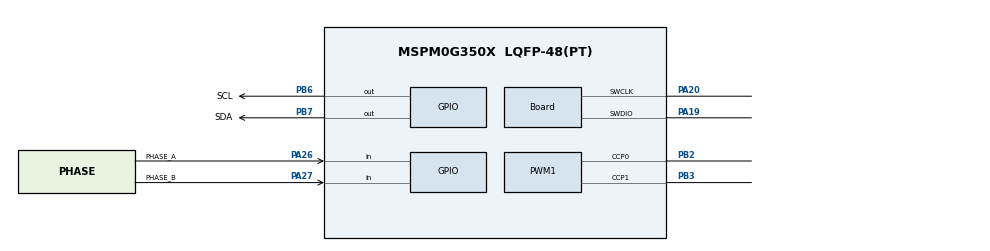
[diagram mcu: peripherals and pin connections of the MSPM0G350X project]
/**
 * @cliArgs --device "MSPM0G350X" --package "LQFP-48(PT)" --part "Default" --product "mspm0_sdk@2.01.00.03"
 * @versions {"tool":"1.20.0+3587"}
 */

/**
 * Import the modules used in this configuration.
 */
const GPIO          = scripting.addModule("/ti/driverlib/GPIO", {}, false);
const GPIO1         = GPIO.addInstance();
const GPIO2         = GPIO.addInstance();
const GPIO3         = GPIO.addInstance();
const PWM           = scripting.addModule("/ti/driverlib/PWM", {}, false);
const PWM1          = PWM.addInstance();
const SYSCTL        = scripting.addModule("/ti/driverlib/SYSCTL");
const ProjectConfig = scripting.addModule("/ti/project_config/ProjectConfig");

/**
 * Write custom configuration values to the imported modules.
 */
GPIO1.$name                              = "GPIO_OLED";
GPIO1.associatedPins.create(2);
GPIO1.associatedPins[0].$name            = "SCL";
GPIO1.associatedPins[0].initialValue     = "SET";
GPIO1.associatedPins[0].internalResistor = "PULL_UP";
GPIO1.associatedPins[0].assignedPort     = "PORTB";
GPIO1.associatedPins[0].assignedPin      = "6";
GPIO1.associatedPins[0].pin.$assign      = "PB6";
GPIO1.associatedPins[1].$name            = "SDA";
GPIO1.associatedPins[1].initialValue     = "SET";
GPIO1.associatedPins[1].internalResistor = "PULL_UP";
GPIO1.associatedPins[1].assignedPort     = "PORTB";
GPIO1.associatedPins[1].assignedPin      = "7";
GPIO1.associatedPins[1].pin.$assign      = "PB7";

const Board                       = scripting.addModule("/ti/driverlib/Board", {}, false);
Board.peripheral.$assign          = "DEBUGSS";
Board.peripheral.swclkPin.$assign = "PA20";
Board.peripheral.swdioPin.$assign = "PA19";

GPIO2.$name                              = "GPIO_ENCODER";
GPIO2.associatedPins.create(2);
GPIO2.associatedPins[0].$name            = "PHASE_A";
GPIO2.associatedPins[0].direction        = "INPUT";
GPIO2.associatedPins[0].internalResistor = "PULL_UP";
GPIO2.associatedPins[0].assignedPort     = "PORTA";
GPIO2.associatedPins[0].assignedPin      = "26";
GPIO2.associatedPins[0].interruptEn      = true;
GPIO2.associatedPins[0].polarity         = "RISE_FALL";
GPIO2.associatedPins[0].pin.$assign      = "PA26";
GPIO2.associatedPins[1].$name            = "PHASE_B";
GPIO2.associatedPins[1].direction        = "INPUT";
GPIO2.associatedPins[1].internalResistor = "PULL_UP";
GPIO2.associatedPins[1].assignedPort     = "PORTA";
GPIO2.associatedPins[1].assignedPin      = "27";
GPIO2.associatedPins[1].interruptEn      = true;
GPIO2.associatedPins[1].polarity         = "RISE_FALL";
GPIO2.associatedPins[1].pin.$assign      = "PA27";

GPIO3.$name                          = "GPIO_MOTOR";
GPIO3.associatedPins.create(4);
GPIO3.associatedPins[0].$name        = "LIN1";
GPIO3.associatedPins[0].assignedPort = "PORTB";
GPIO3.associatedPins[0].assignedPin  = "18";
GPIO3.associatedPins[1].$name        = "LIN2";
GPIO3.associatedPins[1].assignedPort = "PORTB";
GPIO3.associatedPins[1].assignedPin  = "14";
GPIO3.associatedPins[2].$name        = "RIN1";
GPIO3.associatedPins[2].assignedPort = "PORTB";
GPIO3.associatedPins[2].assignedPin  = "15";
GPIO3.associatedPins[3].$name        = "RIN2";
GPIO3.associatedPins[3].assignedPort = "PORTB";
GPIO3.associatedPins[3].assignedPin  = "9";

PWM1.pwmMode                            = "EDGE_ALIGN_UP";
PWM1.$name                              = "PWM_MOTOR";
PWM1.peripheral.$assign                 = "TIMA1";
PWM1.peripheral.ccp0Pin.$assign         = "PB2";
PWM1.peripheral.ccp1Pin.$assign         = "PB3";
PWM1.PWM_CHANNEL_0.$name                = "ti_driverlib_pwm_PWMTimerCC0";
PWM1.PWM_CHANNEL_1.$name                = "ti_driverlib_pwm_PWMTimerCC1";
PWM1.ccp0PinConfig.$name                = "ti_driverlib_gpio_GPIOPinGeneric0";
PWM1.ccp0PinConfig.direction            = scripting.forceWrite("OUTPUT");
PWM1.ccp0PinConfig.hideOutputInversion  = scripting.forceWrite(false);
PWM1.ccp0PinConfig.onlyInternalResistor = scripting.forceWrite(false);
PWM1.ccp0PinConfig.passedPeripheralType = scripting.forceWrite("Digital");
PWM1.ccp1PinConfig.$name                = "ti_driverlib_gpio_GPIOPinGeneric1";
PWM1.ccp1PinConfig.direction            = scripting.forceWrite("OUTPUT");
PWM1.ccp1PinConfig.hideOutputInversion  = scripting.forceWrite(false);
PWM1.ccp1PinConfig.onlyInternalResistor = scripting.forceWrite(false);
PWM1.ccp1PinConfig.passedPeripheralType = scripting.forceWrite("Digital");

SYSCTL.forceDefaultClkConfig = true;
SYSCTL.peripheral.$assign    = "SYSCTL";

ProjectConfig.deviceSpin = "MSPM0G3507";

/**
 * Pinmux solution for unlocked pins/peripherals. This ensures that minor changes to the automatic solver in a future
 * version of the tool will not impact the pinmux you originally saw.  These lines can be completely deleted in order to
 * re-solve from scratch.
 */
GPIO3.associatedPins[0].pin.$suggestSolution = "PB18";
GPIO3.associatedPins[1].pin.$suggestSolution = "PB14";
GPIO3.associatedPins[2].pin.$suggestSolution = "PB15";
GPIO3.associatedPins[3].pin.$suggestSolution = "PB9";
